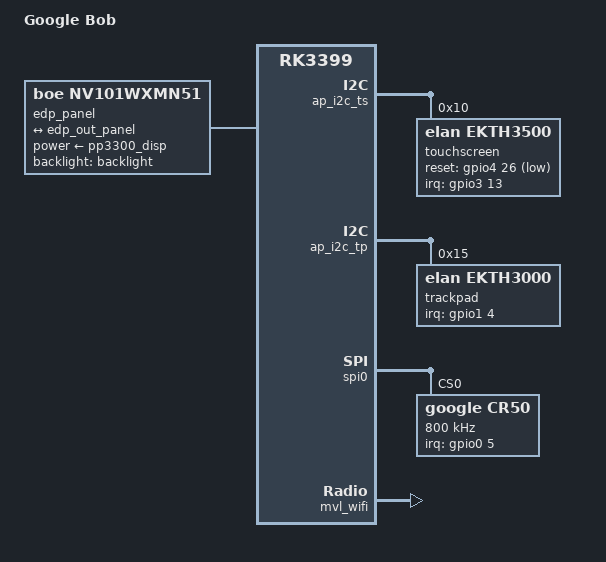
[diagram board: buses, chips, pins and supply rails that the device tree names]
// SPDX-License-Identifier: (GPL-2.0+ OR MIT)
/*
 * Google Gru-Bob Rev 4+ board device tree source
 *
 * Copyright 2018 Google, Inc
 */

/dts-v1/;
#include "rk3399-gru-chromebook.dtsi"

/ {
	model = "Google Bob";
	compatible = "google,bob-rev13", "google,bob-rev12",
		     "google,bob-rev11", "google,bob-rev10",
		     "google,bob-rev9", "google,bob-rev8",
		     "google,bob-rev7", "google,bob-rev6",
		     "google,bob-rev5", "google,bob-rev4",
		     "google,bob", "google,gru", "rockchip,rk3399";

	edp_panel: edp-panel {
		compatible = "boe,nv101wxmn51";
		backlight = <&backlight>;
		power-supply = <&pp3300_disp>;

		port {
			panel_in_edp: endpoint {
				remote-endpoint = <&edp_out_panel>;
			};
		};
	};
};

&ap_i2c_ts {
	touchscreen: touchscreen@10 {
		compatible = "elan,ekth3500";
		reg = <0x10>;
		interrupt-parent = <&gpio3>;
		interrupts = <13 IRQ_TYPE_LEVEL_LOW>;
		pinctrl-names = "default";
		pinctrl-0 = <&touch_int_l &touch_reset_l>;
		reset-gpios = <&gpio4 26 GPIO_ACTIVE_LOW>;
	};
};

&ap_i2c_tp {
	trackpad: trackpad@15 {
		compatible = "elan,ekth3000";
		reg = <0x15>;
		interrupt-parent = <&gpio1>;
		interrupts = <4 IRQ_TYPE_LEVEL_LOW>;
		pinctrl-names = "default";
		pinctrl-0 = <&trackpad_int_l>;
		wakeup-source;
	};
};

&backlight {
	pwms = <&cros_ec_pwm 0>;
};

&cpu_alert0 {
	temperature = <65000>;
};

&cpu_alert1 {
	temperature = <70000>;
};

&spi0 {
	status = "okay";

	cr50@0 {
		compatible = "google,cr50";
		reg = <0>;
		interrupt-parent = <&gpio0>;
		interrupts = <5 IRQ_TYPE_EDGE_RISING>;
		pinctrl-names = "default";
		pinctrl-0 = <&h1_int_od_l>;
		spi-max-frequency = <800000>;
	};
};

&mvl_wifi {
	marvell,caldata_00_txpwrlimit_2g_cfg_set = /bits/ 8 <
0x01 0x00 0x06 0x00 0x30 0x02 0x89 0x01 0x24 0x00 0x67 0x09 0x14 0x01 0x00 0x0d
0x01 0x0d 0x02 0x0d 0x03 0x0d 0x04 0x0d 0x05 0x0d 0x06 0x0d 0x07 0x0d 0x08 0x0d
0x09 0x0d 0x0a 0x0d 0x0b 0x0d 0x0c 0x0d 0x0d 0x0d 0x0e 0x0d 0x0f 0x0d 0x89 0x01
0x24 0x00 0x67 0x09 0x14 0x02 0x00 0x0d 0x01 0x0d 0x02 0x0d 0x03 0x0d 0x04 0x0d
0x05 0x0d 0x06 0x0d 0x07 0x0d 0x08 0x0d 0x09 0x0d 0x0a 0x0d 0x0b 0x0d 0x0c 0x0d
0x0d 0x0d 0x0e 0x0d 0x0f 0x0d 0x89 0x01 0x24 0x00 0x67 0x09 0x14 0x03 0x00 0x0d
0x01 0x0d 0x02 0x0d 0x03 0x0d 0x04 0x0d 0x05 0x0d 0x06 0x0d 0x07 0x0d 0x08 0x0d
0x09 0x0d 0x0a 0x0d 0x0b 0x0d 0x0c 0x0d 0x0d 0x0d 0x0e 0x0d 0x0f 0x0d 0x89 0x01
0x24 0x00 0x67 0x09 0x14 0x04 0x00 0x0d 0x01 0x0d 0x02 0x0d 0x03 0x0d 0x04 0x0d
0x05 0x0d 0x06 0x0d 0x07 0x0d 0x08 0x0d 0x09 0x0d 0x0a 0x0d 0x0b 0x0d 0x0c 0x0d
0x0d 0x0d 0x0e 0x0d 0x0f 0x0d 0x89 0x01 0x24 0x00 0x67 0x09 0x14 0x05 0x00 0x0d
0x01 0x0d 0x02 0x0d 0x03 0x0d 0x04 0x0d 0x05 0x0d 0x06 0x0d 0x07 0x0d 0x08 0x0d
0x09 0x0d 0x0a 0x0d 0x0b 0x0d 0x0c 0x0d 0x0d 0x0d 0x0e 0x0d 0x0f 0x0d 0x89 0x01
0x24 0x00 0x67 0x09 0x14 0x06 0x00 0x0d 0x01 0x0d 0x02 0x0d 0x03 0x0d 0x04 0x0d
0x05 0x0d 0x06 0x0d 0x07 0x0d 0x08 0x0d 0x09 0x0d 0x0a 0x0d 0x0b 0x0d 0x0c 0x0d
0x0d 0x0d 0x0e 0x0d 0x0f 0x0d 0x89 0x01 0x24 0x00 0x67 0x09 0x14 0x07 0x00 0x0d
0x01 0x0d 0x02 0x0d 0x03 0x0d 0x04 0x0d 0x05 0x0d 0x06 0x0d 0x07 0x0d 0x08 0x0d
0x09 0x0d 0x0a 0x0d 0x0b 0x0d 0x0c 0x0d 0x0d 0x0d 0x0e 0x0d 0x0f 0x0d 0x89 0x01
0x24 0x00 0x67 0x09 0x14 0x08 0x00 0x0d 0x01 0x0d 0x02 0x0d 0x03 0x0d 0x04 0x0d
0x05 0x0d 0x06 0x0d 0x07 0x0d 0x08 0x0d 0x09 0x0d 0x0a 0x0d 0x0b 0x0d 0x0c 0x0d
0x0d 0x0d 0x0e 0x0d 0x0f 0x0d 0x89 0x01 0x24 0x00 0x67 0x09 0x14 0x09 0x00 0x0d
0x01 0x0d 0x02 0x0d 0x03 0x0d 0x04 0x0d 0x05 0x0d 0x06 0x0d 0x07 0x0d 0x08 0x0d
0x09 0x0d 0x0a 0x0d 0x0b 0x0d 0x0c 0x0d 0x0d 0x0d 0x0e 0x0d 0x0f 0x0d 0x89 0x01
0x24 0x00 0x67 0x09 0x14 0x0a 0x00 0x0d 0x01 0x0d 0x02 0x0d 0x03 0x0d 0x04 0x0d
0x05 0x0d 0x06 0x0d 0x07 0x0d 0x08 0x0d 0x09 0x0d 0x0a 0x0d 0x0b 0x0d 0x0c 0x0d
0x0d 0x0d 0x0e 0x0d 0x0f 0x0d 0x89 0x01 0x24 0x00 0x67 0x09 0x14 0x0b 0x00 0x0d
0x01 0x0d 0x02 0x0d 0x03 0x0d 0x04 0x0d 0x05 0x0d 0x06 0x0d 0x07 0x0d 0x08 0x0d
0x09 0x0d 0x0a 0x0d 0x0b 0x0d 0x0c 0x0d 0x0d 0x0d 0x0e 0x0d 0x0f 0x0d 0x89 0x01
0x24 0x00 0x67 0x09 0x14 0x0c 0x00 0x0d 0x01 0x0d 0x02 0x0d 0x03 0x0d 0x04 0x0d
0x05 0x0d 0x06 0x0d 0x07 0x0d 0x08 0x0d 0x09 0x0d 0x0a 0x0d 0x0b 0x0d 0x0c 0x0d
0x0d 0x0d 0x0e 0x0d 0x0f 0x0d 0x89 0x01 0x24 0x00 0x67 0x09 0x14 0x0d 0x00 0x0d
0x01 0x0d 0x02 0x0d 0x03 0x0d 0x04 0x0d 0x05 0x0d 0x06 0x0d 0x07 0x0d 0x08 0x0d
0x09 0x0d 0x0a 0x0d 0x0b 0x0d 0x0c 0x0d 0x0d 0x0d 0x0e 0x0d 0x0f 0x0d 0x89 0x01
0x24 0x00 0x67 0x09 0x14 0x0e 0x00 0x0d 0x01 0x0d 0x02 0x0d 0x03 0x0d 0x04 0x0d
0x05 0x0d 0x06 0x0d 0x07 0x0d 0x08 0x0d 0x09 0x0d 0x0a 0x0d 0x0b 0x0d 0x0c 0x0d
0x0d 0x0d 0x0e 0x0d 0x0f 0x0d
	>;

	marvell,caldata_00_txpwrlimit_5g_cfg_set_sub0 = /bits/ 8 <
0x01 0x00 0x06 0x00 0x04 0x02 0x89 0x01 0x3c 0x00 0x88 0x13 0x14 0x24 0x00 0x0a
0x01 0x0a 0x02 0x0a 0x03 0x0a 0x04 0x0a 0x05 0x0a 0x06 0x0a 0x07 0x0a 0x08 0x0a
0x09 0x0a 0x0a 0x0a 0x0b 0x0a 0x0c 0x0a 0x0d 0x0a 0x0e 0x0a 0x0f 0x0a 0x10 0x0a
0x11 0x0a 0x12 0x0a 0x13 0x0a 0x14 0x0a 0x15 0x0a 0x16 0x0a 0x17 0x0a 0x18 0x0a
0x19 0x0a 0x1a 0x0a 0x1b 0x0a 0x89 0x01 0x3c 0x00 0x88 0x13 0x14 0x28 0x00 0x0a
0x01 0x0a 0x02 0x0a 0x03 0x0a 0x04 0x0a 0x05 0x0a 0x06 0x0a 0x07 0x0a 0x08 0x0a
0x09 0x0a 0x0a 0x0a 0x0b 0x0a 0x0c 0x0a 0x0d 0x0a 0x0e 0x0a 0x0f 0x0a 0x10 0x0a
0x11 0x0a 0x12 0x0a 0x13 0x0a 0x14 0x0a 0x15 0x0a 0x16 0x0a 0x17 0x0a 0x18 0x0a
0x19 0x0a 0x1a 0x0a 0x1b 0x0a 0x89 0x01 0x3c 0x00 0x88 0x13 0x14 0x2c 0x00 0x0a
0x01 0x0a 0x02 0x0a 0x03 0x0a 0x04 0x0a 0x05 0x0a 0x06 0x0a 0x07 0x0a 0x08 0x0a
0x09 0x0a 0x0a 0x0a 0x0b 0x0a 0x0c 0x0a 0x0d 0x0a 0x0e 0x0a 0x0f 0x0a 0x10 0x0a
0x11 0x0a 0x12 0x0a 0x13 0x0a 0x14 0x0a 0x15 0x0a 0x16 0x0a 0x17 0x0a 0x18 0x0a
0x19 0x0a 0x1a 0x0a 0x1b 0x0a 0x89 0x01 0x3c 0x00 0x88 0x13 0x14 0x30 0x00 0x0a
0x01 0x0a 0x02 0x0a 0x03 0x0a 0x04 0x0a 0x05 0x0a 0x06 0x0a 0x07 0x0a 0x08 0x0a
0x09 0x0a 0x0a 0x0a 0x0b 0x0a 0x0c 0x0a 0x0d 0x0a 0x0e 0x0a 0x0f 0x0a 0x10 0x0a
0x11 0x0a 0x12 0x0a 0x13 0x0a 0x14 0x0a 0x15 0x0a 0x16 0x0a 0x17 0x0a 0x18 0x0a
0x19 0x0a 0x1a 0x0a 0x1b 0x0a 0x89 0x01 0x3c 0x00 0x88 0x13 0x14 0x34 0x00 0x0a
0x01 0x0a 0x02 0x0a 0x03 0x0a 0x04 0x0a 0x05 0x0a 0x06 0x0a 0x07 0x0a 0x08 0x0a
0x09 0x0a 0x0a 0x0a 0x0b 0x0a 0x0c 0x0a 0x0d 0x0a 0x0e 0x0a 0x0f 0x0a 0x10 0x0a
0x11 0x0a 0x12 0x0a 0x13 0x0a 0x14 0x0a 0x15 0x0a 0x16 0x0a 0x17 0x0a 0x18 0x0a
0x19 0x0a 0x1a 0x0a 0x1b 0x0a 0x89 0x01 0x3c 0x00 0x88 0x13 0x14 0x38 0x00 0x0a
0x01 0x0a 0x02 0x0a 0x03 0x0a 0x04 0x0a 0x05 0x0a 0x06 0x0a 0x07 0x0a 0x08 0x0a
0x09 0x0a 0x0a 0x0a 0x0b 0x0a 0x0c 0x0a 0x0d 0x0a 0x0e 0x0a 0x0f 0x0a 0x10 0x0a
0x11 0x0a 0x12 0x0a 0x13 0x0a 0x14 0x0a 0x15 0x0a 0x16 0x0a 0x17 0x0a 0x18 0x0a
0x19 0x0a 0x1a 0x0a 0x1b 0x0a 0x89 0x01 0x3c 0x00 0x88 0x13 0x14 0x3c 0x00 0x0a
0x01 0x0a 0x02 0x0a 0x03 0x0a 0x04 0x0a 0x05 0x0a 0x06 0x0a 0x07 0x0a 0x08 0x0a
0x09 0x0a 0x0a 0x0a 0x0b 0x0a 0x0c 0x0a 0x0d 0x0a 0x0e 0x0a 0x0f 0x0a 0x10 0x0a
0x11 0x0a 0x12 0x0a 0x13 0x0a 0x14 0x0a 0x15 0x0a 0x16 0x0a 0x17 0x0a 0x18 0x0a
0x19 0x0a 0x1a 0x0a 0x1b 0x0a 0x89 0x01 0x3c 0x00 0x88 0x13 0x14 0x40 0x00 0x0a
0x01 0x0a 0x02 0x0a 0x03 0x0a 0x04 0x0a 0x05 0x0a 0x06 0x0a 0x07 0x0a 0x08 0x0a
0x09 0x0a 0x0a 0x0a 0x0b 0x0a 0x0c 0x0a 0x0d 0x0a 0x0e 0x0a 0x0f 0x0a 0x10 0x0a
0x11 0x0a 0x12 0x0a 0x13 0x0a 0x14 0x0a 0x15 0x0a 0x16 0x0a 0x17 0x0a 0x18 0x0a
0x19 0x0a 0x1a 0x0a 0x1b 0x0a
	>;

	marvell,caldata_00_txpwrlimit_5g_cfg_set_sub1 = /bits/ 8 <
0x01 0x00 0x06 0x00 0x04 0x03 0x89 0x01 0x3c 0x00 0x88 0x13 0x14 0x64 0x00 0x0a
0x01 0x0a 0x02 0x0a 0x03 0x0a 0x04 0x0a 0x05 0x0a 0x06 0x0a 0x07 0x0a 0x08 0x0a
0x09 0x0a 0x0a 0x0a 0x0b 0x0a 0x0c 0x0a 0x0d 0x0a 0x0e 0x0a 0x0f 0x0a 0x10 0x0a
0x11 0x0a 0x12 0x0a 0x13 0x0a 0x14 0x0a 0x15 0x0a 0x16 0x0a 0x17 0x0a 0x18 0x0a
0x19 0x0a 0x1a 0x0a 0x1b 0x0a 0x89 0x01 0x3c 0x00 0x88 0x13 0x14 0x68 0x00 0x0a
0x01 0x0a 0x02 0x0a 0x03 0x0a 0x04 0x0a 0x05 0x0a 0x06 0x0a 0x07 0x0a 0x08 0x0a
0x09 0x0a 0x0a 0x0a 0x0b 0x0a 0x0c 0x0a 0x0d 0x0a 0x0e 0x0a 0x0f 0x0a 0x10 0x0a
0x11 0x0a 0x12 0x0a 0x13 0x0a 0x14 0x0a 0x15 0x0a 0x16 0x0a 0x17 0x0a 0x18 0x0a
0x19 0x0a 0x1a 0x0a 0x1b 0x0a 0x89 0x01 0x3c 0x00 0x88 0x13 0x14 0x6c 0x00 0x0a
0x01 0x0a 0x02 0x0a 0x03 0x0a 0x04 0x0a 0x05 0x0a 0x06 0x0a 0x07 0x0a 0x08 0x0a
0x09 0x0a 0x0a 0x0a 0x0b 0x0a 0x0c 0x0a 0x0d 0x0a 0x0e 0x0a 0x0f 0x0a 0x10 0x0a
0x11 0x0a 0x12 0x0a 0x13 0x0a 0x14 0x0a 0x15 0x0a 0x16 0x0a 0x17 0x0a 0x18 0x0a
0x19 0x0a 0x1a 0x0a 0x1b 0x0a 0x89 0x01 0x3c 0x00 0x88 0x13 0x14 0x70 0x00 0x0a
0x01 0x0a 0x02 0x0a 0x03 0x0a 0x04 0x0a 0x05 0x0a 0x06 0x0a 0x07 0x0a 0x08 0x0a
0x09 0x0a 0x0a 0x0a 0x0b 0x0a 0x0c 0x0a 0x0d 0x0a 0x0e 0x0a 0x0f 0x0a 0x10 0x0a
0x11 0x0a 0x12 0x0a 0x13 0x0a 0x14 0x0a 0x15 0x0a 0x16 0x0a 0x17 0x0a 0x18 0x0a
0x19 0x0a 0x1a 0x0a 0x1b 0x0a 0x89 0x01 0x3c 0x00 0x88 0x13 0x14 0x74 0x00 0x0a
0x01 0x0a 0x02 0x0a 0x03 0x0a 0x04 0x0a 0x05 0x0a 0x06 0x0a 0x07 0x0a 0x08 0x0a
0x09 0x0a 0x0a 0x0a 0x0b 0x0a 0x0c 0x0a 0x0d 0x0a 0x0e 0x0a 0x0f 0x0a 0x10 0x0a
0x11 0x0a 0x12 0x0a 0x13 0x0a 0x14 0x0a 0x15 0x0a 0x16 0x0a 0x17 0x0a 0x18 0x0a
0x19 0x0a 0x1a 0x0a 0x1b 0x0a 0x89 0x01 0x3c 0x00 0x88 0x13 0x14 0x78 0x00 0x0a
0x01 0x0a 0x02 0x0a 0x03 0x0a 0x04 0x0a 0x05 0x0a 0x06 0x0a 0x07 0x0a 0x08 0x0a
0x09 0x0a 0x0a 0x0a 0x0b 0x0a 0x0c 0x0a 0x0d 0x0a 0x0e 0x0a 0x0f 0x0a 0x10 0x0a
0x11 0x0a 0x12 0x0a 0x13 0x0a 0x14 0x0a 0x15 0x0a 0x16 0x0a 0x17 0x0a 0x18 0x0a
0x19 0x0a 0x1a 0x0a 0x1b 0x0a 0x89 0x01 0x3c 0x00 0x88 0x13 0x14 0x7c 0x00 0x0a
0x01 0x0a 0x02 0x0a 0x03 0x0a 0x04 0x0a 0x05 0x0a 0x06 0x0a 0x07 0x0a 0x08 0x0a
0x09 0x0a 0x0a 0x0a 0x0b 0x0a 0x0c 0x0a 0x0d 0x0a 0x0e 0x0a 0x0f 0x0a 0x10 0x0a
0x11 0x0a 0x12 0x0a 0x13 0x0a 0x14 0x0a 0x15 0x0a 0x16 0x0a 0x17 0x0a 0x18 0x0a
0x19 0x0a 0x1a 0x0a 0x1b 0x0a 0x89 0x01 0x3c 0x00 0x88 0x13 0x14 0x80 0x00 0x0a
0x01 0x0a 0x02 0x0a 0x03 0x0a 0x04 0x0a 0x05 0x0a 0x06 0x0a 0x07 0x0a 0x08 0x0a
0x09 0x0a 0x0a 0x0a 0x0b 0x0a 0x0c 0x0a 0x0d 0x0a 0x0e 0x0a 0x0f 0x0a 0x10 0x0a
0x11 0x0a 0x12 0x0a 0x13 0x0a 0x14 0x0a 0x15 0x0a 0x16 0x0a 0x17 0x0a 0x18 0x0a
0x19 0x0a 0x1a 0x0a 0x1b 0x0a 0x89 0x01 0x3c 0x00 0x88 0x13 0x14 0x84 0x00 0x0a
0x01 0x0a 0x02 0x0a 0x03 0x0a 0x04 0x0a 0x05 0x0a 0x06 0x0a 0x07 0x0a 0x08 0x0a
0x09 0x0a 0x0a 0x0a 0x0b 0x0a 0x0c 0x0a 0x0d 0x0a 0x0e 0x0a 0x0f 0x0a 0x10 0x0a
0x11 0x0a 0x12 0x0a 0x13 0x0a 0x14 0x0a 0x15 0x0a 0x16 0x0a 0x17 0x0a 0x18 0x0a
0x19 0x0a 0x1a 0x0a 0x1b 0x0a 0x89 0x01 0x3c 0x00 0x88 0x13 0x14 0x88 0x00 0x0a
0x01 0x0a 0x02 0x0a 0x03 0x0a 0x04 0x0a 0x05 0x0a 0x06 0x0a 0x07 0x0a 0x08 0x0a
0x09 0x0a 0x0a 0x0a 0x0b 0x0a 0x0c 0x0a 0x0d 0x0a 0x0e 0x0a 0x0f 0x0a 0x10 0x0a
0x11 0x0a 0x12 0x0a 0x13 0x0a 0x14 0x0a 0x15 0x0a 0x16 0x0a 0x17 0x0a 0x18 0x0a
0x19 0x0a 0x1a 0x0a 0x1b 0x0a 0x89 0x01 0x3c 0x00 0x88 0x13 0x14 0x8c 0x00 0x0a
0x01 0x0a 0x02 0x0a 0x03 0x0a 0x04 0x0a 0x05 0x0a 0x06 0x0a 0x07 0x0a 0x08 0x0a
0x09 0x0a 0x0a 0x0a 0x0b 0x0a 0x0c 0x0a 0x0d 0x0a 0x0e 0x0a 0x0f 0x0a 0x10 0x0a
0x11 0x0a 0x12 0x0a 0x13 0x0a 0x14 0x0a 0x15 0x0a 0x16 0x0a 0x17 0x0a 0x18 0x0a
0x19 0x0a 0x1a 0x0a 0x1b 0x0a 0x89 0x01 0x3c 0x00 0x88 0x13 0x14 0x90 0x00 0x0a
0x01 0x0a 0x02 0x0a 0x03 0x0a 0x04 0x0a 0x05 0x0a 0x06 0x0a 0x07 0x0a 0x08 0x0a
0x09 0x0a 0x0a 0x0a 0x0b 0x0a 0x0c 0x0a 0x0d 0x0a 0x0e 0x0a 0x0f 0x0a 0x10 0x0a
0x11 0x0a 0x12 0x0a 0x13 0x0a 0x14 0x0a 0x15 0x0a 0x16 0x0a 0x17 0x0a 0x18 0x0a
0x19 0x0a 0x1a 0x0a 0x1b 0x0a
	>;

	marvell,caldata_00_txpwrlimit_5g_cfg_set_sub2 = /bits/ 8 <
0x01 0x00 0x06 0x00 0x44 0x01 0x89 0x01 0x3c 0x00 0x88 0x13 0x14 0x95 0x00 0x0a
0x01 0x0a 0x02 0x0a 0x03 0x0a 0x04 0x0a 0x05 0x0a 0x06 0x0a 0x07 0x0a 0x08 0x0a
0x09 0x0a 0x0a 0x0a 0x0b 0x0a 0x0c 0x0a 0x0d 0x0a 0x0e 0x0a 0x0f 0x0a 0x10 0x0a
0x11 0x0a 0x12 0x0a 0x13 0x0a 0x14 0x0a 0x15 0x0a 0x16 0x0a 0x17 0x0a 0x18 0x0a
0x19 0x0a 0x1a 0x0a 0x1b 0x0a 0x89 0x01 0x3c 0x00 0x88 0x13 0x14 0x99 0x00 0x0a
0x01 0x0a 0x02 0x0a 0x03 0x0a 0x04 0x0a 0x05 0x0a 0x06 0x0a 0x07 0x0a 0x08 0x0a
0x09 0x0a 0x0a 0x0a 0x0b 0x0a 0x0c 0x0a 0x0d 0x0a 0x0e 0x0a 0x0f 0x0a 0x10 0x0a
0x11 0x0a 0x12 0x0a 0x13 0x0a 0x14 0x0a 0x15 0x0a 0x16 0x0a 0x17 0x0a 0x18 0x0a
0x19 0x0a 0x1a 0x0a 0x1b 0x0a 0x89 0x01 0x3c 0x00 0x88 0x13 0x14 0x9d 0x00 0x0a
0x01 0x0a 0x02 0x0a 0x03 0x0a 0x04 0x0a 0x05 0x0a 0x06 0x0a 0x07 0x0a 0x08 0x0a
0x09 0x0a 0x0a 0x0a 0x0b 0x0a 0x0c 0x0a 0x0d 0x0a 0x0e 0x0a 0x0f 0x0a 0x10 0x0a
0x11 0x0a 0x12 0x0a 0x13 0x0a 0x14 0x0a 0x15 0x0a 0x16 0x0a 0x17 0x0a 0x18 0x0a
0x19 0x0a 0x1a 0x0a 0x1b 0x0a 0x89 0x01 0x3c 0x00 0x88 0x13 0x14 0xa1 0x00 0x0a
0x01 0x0a 0x02 0x0a 0x03 0x0a 0x04 0x0a 0x05 0x0a 0x06 0x0a 0x07 0x0a 0x08 0x0a
0x09 0x0a 0x0a 0x0a 0x0b 0x0a 0x0c 0x0a 0x0d 0x0a 0x0e 0x0a 0x0f 0x0a 0x10 0x0a
0x11 0x0a 0x12 0x0a 0x13 0x0a 0x14 0x0a 0x15 0x0a 0x16 0x0a 0x17 0x0a 0x18 0x0a
0x19 0x0a 0x1a 0x0a 0x1b 0x0a 0x89 0x01 0x3c 0x00 0x88 0x13 0x14 0xa5 0x00 0x0a
0x01 0x0a 0x02 0x0a 0x03 0x0a 0x04 0x0a 0x05 0x0a 0x06 0x0a 0x07 0x0a 0x08 0x0a
0x09 0x0a 0x0a 0x0a 0x0b 0x0a 0x0c 0x0a 0x0d 0x0a 0x0e 0x0a 0x0f 0x0a 0x10 0x0a
0x11 0x0a 0x12 0x0a 0x13 0x0a 0x14 0x0a 0x15 0x0a 0x16 0x0a 0x17 0x0a 0x18 0x0a
0x19 0x0a 0x1a 0x0a 0x1b 0x0a
	>;

	marvell,caldata_00_txpwrlimit_5g_cfg_set_sub3 = /bits/ 8 <
0x01 0x00 0x06 0x00 0x84 0x03 0x89 0x01 0x3c 0x00 0xa0 0x0f 0x14 0xb7 0x00 0x0a
0x01 0x0a 0x02 0x0a 0x03 0x0a 0x04 0x0a 0x05 0x0a 0x06 0x0a 0x07 0x0a 0x08 0x0a
0x09 0x0a 0x0a 0x0a 0x0b 0x0a 0x0c 0x0a 0x0d 0x0a 0x0e 0x0a 0x0f 0x0a 0x10 0x0a
0x11 0x0a 0x12 0x0a 0x13 0x0a 0x14 0x0a 0x15 0x0a 0x16 0x0a 0x17 0x0a 0x18 0x0a
0x19 0x0a 0x1a 0x0a 0x1b 0x0a 0x89 0x01 0x3c 0x00 0xa0 0x0f 0x14 0xb8 0x00 0x0a
0x01 0x0a 0x02 0x0a 0x03 0x0a 0x04 0x0a 0x05 0x0a 0x06 0x0a 0x07 0x0a 0x08 0x0a
0x09 0x0a 0x0a 0x0a 0x0b 0x0a 0x0c 0x0a 0x0d 0x0a 0x0e 0x0a 0x0f 0x0a 0x10 0x0a
0x11 0x0a 0x12 0x0a 0x13 0x0a 0x14 0x0a 0x15 0x0a 0x16 0x0a 0x17 0x0a 0x18 0x0a
0x19 0x0a 0x1a 0x0a 0x1b 0x0a 0x89 0x01 0x3c 0x00 0xa0 0x0f 0x14 0xb9 0x00 0x0a
0x01 0x0a 0x02 0x0a 0x03 0x0a 0x04 0x0a 0x05 0x0a 0x06 0x0a 0x07 0x0a 0x08 0x0a
0x09 0x0a 0x0a 0x0a 0x0b 0x0a 0x0c 0x0a 0x0d 0x0a 0x0e 0x0a 0x0f 0x0a 0x10 0x0a
0x11 0x0a 0x12 0x0a 0x13 0x0a 0x14 0x0a 0x15 0x0a 0x16 0x0a 0x17 0x0a 0x18 0x0a
0x19 0x0a 0x1a 0x0a 0x1b 0x0a 0x89 0x01 0x3c 0x00 0xa0 0x0f 0x14 0xbb 0x00 0x0a
0x01 0x0a 0x02 0x0a 0x03 0x0a 0x04 0x0a 0x05 0x0a 0x06 0x0a 0x07 0x0a 0x08 0x0a
0x09 0x0a 0x0a 0x0a 0x0b 0x0a 0x0c 0x0a 0x0d 0x0a 0x0e 0x0a 0x0f 0x0a 0x10 0x0a
0x11 0x0a 0x12 0x0a 0x13 0x0a 0x14 0x0a 0x15 0x0a 0x16 0x0a 0x17 0x0a 0x18 0x0a
0x19 0x0a 0x1a 0x0a 0x1b 0x0a 0x89 0x01 0x3c 0x00 0xa0 0x0f 0x14 0xbc 0x00 0x0a
0x01 0x0a 0x02 0x0a 0x03 0x0a 0x04 0x0a 0x05 0x0a 0x06 0x0a 0x07 0x0a 0x08 0x0a
0x09 0x0a 0x0a 0x0a 0x0b 0x0a 0x0c 0x0a 0x0d 0x0a 0x0e 0x0a 0x0f 0x0a 0x10 0x0a
0x11 0x0a 0x12 0x0a 0x13 0x0a 0x14 0x0a 0x15 0x0a 0x16 0x0a 0x17 0x0a 0x18 0x0a
0x19 0x0a 0x1a 0x0a 0x1b 0x0a 0x89 0x01 0x3c 0x00 0xa0 0x0f 0x14 0xbd 0x00 0x0a
0x01 0x0a 0x02 0x0a 0x03 0x0a 0x04 0x0a 0x05 0x0a 0x06 0x0a 0x07 0x0a 0x08 0x0a
0x09 0x0a 0x0a 0x0a 0x0b 0x0a 0x0c 0x0a 0x0d 0x0a 0x0e 0x0a 0x0f 0x0a 0x10 0x0a
0x11 0x0a 0x12 0x0a 0x13 0x0a 0x14 0x0a 0x15 0x0a 0x16 0x0a 0x17 0x0a 0x18 0x0a
0x19 0x0a 0x1a 0x0a 0x1b 0x0a 0x89 0x01 0x3c 0x00 0xa0 0x0f 0x14 0xc0 0x00 0x0a
0x01 0x0a 0x02 0x0a 0x03 0x0a 0x04 0x0a 0x05 0x0a 0x06 0x0a 0x07 0x0a 0x08 0x0a
0x09 0x0a 0x0a 0x0a 0x0b 0x0a 0x0c 0x0a 0x0d 0x0a 0x0e 0x0a 0x0f 0x0a 0x10 0x0a
0x11 0x0a 0x12 0x0a 0x13 0x0a 0x14 0x0a 0x15 0x0a 0x16 0x0a 0x17 0x0a 0x18 0x0a
0x19 0x0a 0x1a 0x0a 0x1b 0x0a 0x89 0x01 0x3c 0x00 0xa0 0x0f 0x14 0xc4 0x00 0x0a
0x01 0x0a 0x02 0x0a 0x03 0x0a 0x04 0x0a 0x05 0x0a 0x06 0x0a 0x07 0x0a 0x08 0x0a
0x09 0x0a 0x0a 0x0a 0x0b 0x0a 0x0c 0x0a 0x0d 0x0a 0x0e 0x0a 0x0f 0x0a 0x10 0x0a
0x11 0x0a 0x12 0x0a 0x13 0x0a 0x14 0x0a 0x15 0x0a 0x16 0x0a 0x17 0x0a 0x18 0x0a
0x19 0x0a 0x1a 0x0a 0x1b 0x0a 0x89 0x01 0x3c 0x00 0x88 0x13 0x14 0x07 0x00 0x0a
0x01 0x0a 0x02 0x0a 0x03 0x0a 0x04 0x0a 0x05 0x0a 0x06 0x0a 0x07 0x0a 0x08 0x0a
0x09 0x0a 0x0a 0x0a 0x0b 0x0a 0x0c 0x0a 0x0d 0x0a 0x0e 0x0a 0x0f 0x0a 0x10 0x0a
0x11 0x0a 0x12 0x0a 0x13 0x0a 0x14 0x0a 0x15 0x0a 0x16 0x0a 0x17 0x0a 0x18 0x0a
0x19 0x0a 0x1a 0x0a 0x1b 0x0a 0x89 0x01 0x3c 0x00 0x88 0x13 0x14 0x08 0x00 0x0a
0x01 0x0a 0x02 0x0a 0x03 0x0a 0x04 0x0a 0x05 0x0a 0x06 0x0a 0x07 0x0a 0x08 0x0a
0x09 0x0a 0x0a 0x0a 0x0b 0x0a 0x0c 0x0a 0x0d 0x0a 0x0e 0x0a 0x0f 0x0a 0x10 0x0a
0x11 0x0a 0x12 0x0a 0x13 0x0a 0x14 0x0a 0x15 0x0a 0x16 0x0a 0x17 0x0a 0x18 0x0a
0x19 0x0a 0x1a 0x0a 0x1b 0x0a 0x89 0x01 0x3c 0x00 0x88 0x13 0x14 0x0b 0x00 0x0a
0x01 0x0a 0x02 0x0a 0x03 0x0a 0x04 0x0a 0x05 0x0a 0x06 0x0a 0x07 0x0a 0x08 0x0a
0x09 0x0a 0x0a 0x0a 0x0b 0x0a 0x0c 0x0a 0x0d 0x0a 0x0e 0x0a 0x0f 0x0a 0x10 0x0a
0x11 0x0a 0x12 0x0a 0x13 0x0a 0x14 0x0a 0x15 0x0a 0x16 0x0a 0x17 0x0a 0x18 0x0a
0x19 0x0a 0x1a 0x0a 0x1b 0x0a 0x89 0x01 0x3c 0x00 0x88 0x13 0x14 0x0c 0x00 0x0a
0x01 0x0a 0x02 0x0a 0x03 0x0a 0x04 0x0a 0x05 0x0a 0x06 0x0a 0x07 0x0a 0x08 0x0a
0x09 0x0a 0x0a 0x0a 0x0b 0x0a 0x0c 0x0a 0x0d 0x0a 0x0e 0x0a 0x0f 0x0a 0x10 0x0a
0x11 0x0a 0x12 0x0a 0x13 0x0a 0x14 0x0a 0x15 0x0a 0x16 0x0a 0x17 0x0a 0x18 0x0a
0x19 0x0a 0x1a 0x0a 0x1b 0x0a 0x89 0x01 0x3c 0x00 0x88 0x13 0x14 0x10 0x00 0x0a
0x01 0x0a 0x02 0x0a 0x03 0x0a 0x04 0x0a 0x05 0x0a 0x06 0x0a 0x07 0x0a 0x08 0x0a
0x09 0x0a 0x0a 0x0a 0x0b 0x0a 0x0c 0x0a 0x0d 0x0a 0x0e 0x0a 0x0f 0x0a 0x10 0x0a
0x11 0x0a 0x12 0x0a 0x13 0x0a 0x14 0x0a 0x15 0x0a 0x16 0x0a 0x17 0x0a 0x18 0x0a
0x19 0x0a 0x1a 0x0a 0x1b 0x0a 0x89 0x01 0x3c 0x00 0x88 0x13 0x14 0x22 0x00 0x0a
0x01 0x0a 0x02 0x0a 0x03 0x0a 0x04 0x0a 0x05 0x0a 0x06 0x0a 0x07 0x0a 0x08 0x0a
0x09 0x0a 0x0a 0x0a 0x0b 0x0a 0x0c 0x0a 0x0d 0x0a 0x0e 0x0a 0x0f 0x0a 0x10 0x0a
0x11 0x0a 0x12 0x0a 0x13 0x0a 0x14 0x0a 0x15 0x0a 0x16 0x0a 0x17 0x0a 0x18 0x0a
0x19 0x0a 0x1a 0x0a 0x1b 0x0a
	>;

	marvell,caldata_01_txpwrlimit_2g_cfg_set = /bits/ 8 <
0x01 0x00 0x06 0x00 0x30 0x02 0x89 0x01 0x24 0x00 0x67 0x09 0x14 0x01 0x00 0x0f
0x01 0x0f 0x02 0x0f 0x03 0x0f 0x04 0x0f 0x05 0x0f 0x06 0x0f 0x07 0x0f 0x08 0x0f
0x09 0x0f 0x0a 0x0f 0x0b 0x0f 0x0c 0x0f 0x0d 0x0f 0x0e 0x0f 0x0f 0x0f 0x89 0x01
0x24 0x00 0x67 0x09 0x14 0x02 0x00 0x0f 0x01 0x0f 0x02 0x0f 0x03 0x0f 0x04 0x0f
0x05 0x0f 0x06 0x0f 0x07 0x0f 0x08 0x0f 0x09 0x0f 0x0a 0x0f 0x0b 0x0f 0x0c 0x0f
0x0d 0x0f 0x0e 0x0f 0x0f 0x0f 0x89 0x01 0x24 0x00 0x67 0x09 0x14 0x03 0x00 0x0f
0x01 0x0f 0x02 0x0f 0x03 0x0f 0x04 0x0f 0x05 0x0f 0x06 0x0f 0x07 0x0f 0x08 0x0f
0x09 0x0f 0x0a 0x0f 0x0b 0x0f 0x0c 0x0f 0x0d 0x0f 0x0e 0x0f 0x0f 0x0f 0x89 0x01
0x24 0x00 0x67 0x09 0x14 0x04 0x00 0x0f 0x01 0x0f 0x02 0x0f 0x03 0x0f 0x04 0x0f
0x05 0x0f 0x06 0x0f 0x07 0x0f 0x08 0x0f 0x09 0x0f 0x0a 0x0f 0x0b 0x0f 0x0c 0x0f
0x0d 0x0f 0x0e 0x0f 0x0f 0x0f 0x89 0x01 0x24 0x00 0x67 0x09 0x14 0x05 0x00 0x0f
0x01 0x0f 0x02 0x0f 0x03 0x0f 0x04 0x0f 0x05 0x0f 0x06 0x0f 0x07 0x0f 0x08 0x0f
0x09 0x0f 0x0a 0x0f 0x0b 0x0f 0x0c 0x0f 0x0d 0x0f 0x0e 0x0f 0x0f 0x0f 0x89 0x01
0x24 0x00 0x67 0x09 0x14 0x06 0x00 0x0f 0x01 0x0f 0x02 0x0f 0x03 0x0f 0x04 0x0f
0x05 0x0f 0x06 0x0f 0x07 0x0f 0x08 0x0f 0x09 0x0f 0x0a 0x0f 0x0b 0x0f 0x0c 0x0f
0x0d 0x0f 0x0e 0x0f 0x0f 0x0f 0x89 0x01 0x24 0x00 0x67 0x09 0x14 0x07 0x00 0x0f
0x01 0x0f 0x02 0x0f 0x03 0x0f 0x04 0x0f 0x05 0x0f 0x06 0x0f 0x07 0x0f 0x08 0x0f
0x09 0x0f 0x0a 0x0f 0x0b 0x0f 0x0c 0x0f 0x0d 0x0f 0x0e 0x0f 0x0f 0x0f 0x89 0x01
0x24 0x00 0x67 0x09 0x14 0x08 0x00 0x0f 0x01 0x0f 0x02 0x0f 0x03 0x0f 0x04 0x0f
0x05 0x0f 0x06 0x0f 0x07 0x0f 0x08 0x0f 0x09 0x0f 0x0a 0x0f 0x0b 0x0f 0x0c 0x0f
0x0d 0x0f 0x0e 0x0f 0x0f 0x0f 0x89 0x01 0x24 0x00 0x67 0x09 0x14 0x09 0x00 0x0f
0x01 0x0f 0x02 0x0f 0x03 0x0f 0x04 0x0f 0x05 0x0f 0x06 0x0f 0x07 0x0f 0x08 0x0f
0x09 0x0f 0x0a 0x0f 0x0b 0x0f 0x0c 0x0f 0x0d 0x0f 0x0e 0x0f 0x0f 0x0f 0x89 0x01
0x24 0x00 0x67 0x09 0x14 0x0a 0x00 0x0f 0x01 0x0f 0x02 0x0f 0x03 0x0f 0x04 0x0f
0x05 0x0f 0x06 0x0f 0x07 0x0f 0x08 0x0f 0x09 0x0f 0x0a 0x0f 0x0b 0x0f 0x0c 0x0f
0x0d 0x0f 0x0e 0x0f 0x0f 0x0f 0x89 0x01 0x24 0x00 0x67 0x09 0x14 0x0b 0x00 0x0f
0x01 0x0f 0x02 0x0f 0x03 0x0f 0x04 0x0f 0x05 0x0f 0x06 0x0f 0x07 0x0f 0x08 0x0f
0x09 0x0f 0x0a 0x0f 0x0b 0x0f 0x0c 0x0f 0x0d 0x0f 0x0e 0x0f 0x0f 0x0f 0x89 0x01
0x24 0x00 0x67 0x09 0x14 0x0c 0x00 0x0f 0x01 0x0f 0x02 0x0f 0x03 0x0f 0x04 0x0f
0x05 0x0f 0x06 0x0f 0x07 0x0f 0x08 0x0f 0x09 0x0f 0x0a 0x0f 0x0b 0x0f 0x0c 0x0f
0x0d 0x0f 0x0e 0x0f 0x0f 0x0f 0x89 0x01 0x24 0x00 0x67 0x09 0x14 0x0d 0x00 0x0f
0x01 0x0f 0x02 0x0f 0x03 0x0f 0x04 0x0f 0x05 0x0f 0x06 0x0f 0x07 0x0f 0x08 0x0f
0x09 0x0f 0x0a 0x0f 0x0b 0x0f 0x0c 0x0f 0x0d 0x0f 0x0e 0x0f 0x0f 0x0f 0x89 0x01
0x24 0x00 0x67 0x09 0x14 0x0e 0x00 0x0f 0x01 0x0f 0x02 0x0f 0x03 0x0f 0x04 0x0f
0x05 0x0f 0x06 0x0f 0x07 0x0f 0x08 0x0f 0x09 0x0f 0x0a 0x0f 0x0b 0x0f 0x0c 0x0f
0x0d 0x0f 0x0e 0x0f 0x0f 0x0f
	>;

	marvell,caldata_01_txpwrlimit_5g_cfg_set_sub0 = /bits/ 8 <
0x01 0x00 0x06 0x00 0x04 0x02 0x89 0x01 0x3c 0x00 0x88 0x13 0x14 0x24 0x00 0x0a
0x01 0x0a 0x02 0x0a 0x03 0x0a 0x04 0x0a 0x05 0x0a 0x06 0x0a 0x07 0x0a 0x08 0x0a
0x09 0x0a 0x0a 0x0a 0x0b 0x0a 0x0c 0x0a 0x0d 0x0a 0x0e 0x0a 0x0f 0x0a 0x10 0x0a
0x11 0x0a 0x12 0x0a 0x13 0x0a 0x14 0x0a 0x15 0x0a 0x16 0x0a 0x17 0x0a 0x18 0x0a
0x19 0x0a 0x1a 0x0a 0x1b 0x0a 0x89 0x01 0x3c 0x00 0x88 0x13 0x14 0x28 0x00 0x0a
0x01 0x0a 0x02 0x0a 0x03 0x0a 0x04 0x0a 0x05 0x0a 0x06 0x0a 0x07 0x0a 0x08 0x0a
0x09 0x0a 0x0a 0x0a 0x0b 0x0a 0x0c 0x0a 0x0d 0x0a 0x0e 0x0a 0x0f 0x0a 0x10 0x0a
0x11 0x0a 0x12 0x0a 0x13 0x0a 0x14 0x0a 0x15 0x0a 0x16 0x0a 0x17 0x0a 0x18 0x0a
0x19 0x0a 0x1a 0x0a 0x1b 0x0a 0x89 0x01 0x3c 0x00 0x88 0x13 0x14 0x2c 0x00 0x0a
0x01 0x0a 0x02 0x0a 0x03 0x0a 0x04 0x0a 0x05 0x0a 0x06 0x0a 0x07 0x0a 0x08 0x0a
0x09 0x0a 0x0a 0x0a 0x0b 0x0a 0x0c 0x0a 0x0d 0x0a 0x0e 0x0a 0x0f 0x0a 0x10 0x0a
0x11 0x0a 0x12 0x0a 0x13 0x0a 0x14 0x0a 0x15 0x0a 0x16 0x0a 0x17 0x0a 0x18 0x0a
0x19 0x0a 0x1a 0x0a 0x1b 0x0a 0x89 0x01 0x3c 0x00 0x88 0x13 0x14 0x30 0x00 0x0a
0x01 0x0a 0x02 0x0a 0x03 0x0a 0x04 0x0a 0x05 0x0a 0x06 0x0a 0x07 0x0a 0x08 0x0a
0x09 0x0a 0x0a 0x0a 0x0b 0x0a 0x0c 0x0a 0x0d 0x0a 0x0e 0x0a 0x0f 0x0a 0x10 0x0a
0x11 0x0a 0x12 0x0a 0x13 0x0a 0x14 0x0a 0x15 0x0a 0x16 0x0a 0x17 0x0a 0x18 0x0a
0x19 0x0a 0x1a 0x0a 0x1b 0x0a 0x89 0x01 0x3c 0x00 0x88 0x13 0x14 0x34 0x00 0x0a
0x01 0x0a 0x02 0x0a 0x03 0x0a 0x04 0x0a 0x05 0x0a 0x06 0x0a 0x07 0x0a 0x08 0x0a
0x09 0x0a 0x0a 0x0a 0x0b 0x0a 0x0c 0x0a 0x0d 0x0a 0x0e 0x0a 0x0f 0x0a 0x10 0x0a
0x11 0x0a 0x12 0x0a 0x13 0x0a 0x14 0x0a 0x15 0x0a 0x16 0x0a 0x17 0x0a 0x18 0x0a
0x19 0x0a 0x1a 0x0a 0x1b 0x0a 0x89 0x01 0x3c 0x00 0x88 0x13 0x14 0x38 0x00 0x0a
0x01 0x0a 0x02 0x0a 0x03 0x0a 0x04 0x0a 0x05 0x0a 0x06 0x0a 0x07 0x0a 0x08 0x0a
0x09 0x0a 0x0a 0x0a 0x0b 0x0a 0x0c 0x0a 0x0d 0x0a 0x0e 0x0a 0x0f 0x0a 0x10 0x0a
0x11 0x0a 0x12 0x0a 0x13 0x0a 0x14 0x0a 0x15 0x0a 0x16 0x0a 0x17 0x0a 0x18 0x0a
0x19 0x0a 0x1a 0x0a 0x1b 0x0a 0x89 0x01 0x3c 0x00 0x88 0x13 0x14 0x3c 0x00 0x0a
0x01 0x0a 0x02 0x0a 0x03 0x0a 0x04 0x0a 0x05 0x0a 0x06 0x0a 0x07 0x0a 0x08 0x0a
0x09 0x0a 0x0a 0x0a 0x0b 0x0a 0x0c 0x0a 0x0d 0x0a 0x0e 0x0a 0x0f 0x0a 0x10 0x0a
0x11 0x0a 0x12 0x0a 0x13 0x0a 0x14 0x0a 0x15 0x0a 0x16 0x0a 0x17 0x0a 0x18 0x0a
0x19 0x0a 0x1a 0x0a 0x1b 0x0a 0x89 0x01 0x3c 0x00 0x88 0x13 0x14 0x40 0x00 0x0a
0x01 0x0a 0x02 0x0a 0x03 0x0a 0x04 0x0a 0x05 0x0a 0x06 0x0a 0x07 0x0a 0x08 0x0a
0x09 0x0a 0x0a 0x0a 0x0b 0x0a 0x0c 0x0a 0x0d 0x0a 0x0e 0x0a 0x0f 0x0a 0x10 0x0a
0x11 0x0a 0x12 0x0a 0x13 0x0a 0x14 0x0a 0x15 0x0a 0x16 0x0a 0x17 0x0a 0x18 0x0a
0x19 0x0a 0x1a 0x0a 0x1b 0x0a
	>;

	marvell,caldata_01_txpwrlimit_5g_cfg_set_sub1 = /bits/ 8 <
0x01 0x00 0x06 0x00 0x04 0x03 0x89 0x01 0x3c 0x00 0x88 0x13 0x14 0x64 0x00 0x0a
0x01 0x0a 0x02 0x0a 0x03 0x0a 0x04 0x0a 0x05 0x0a 0x06 0x0a 0x07 0x0a 0x08 0x0a
0x09 0x0a 0x0a 0x0a 0x0b 0x0a 0x0c 0x0a 0x0d 0x0a 0x0e 0x0a 0x0f 0x0a 0x10 0x0a
0x11 0x0a 0x12 0x0a 0x13 0x0a 0x14 0x0a 0x15 0x0a 0x16 0x0a 0x17 0x0a 0x18 0x0a
0x19 0x0a 0x1a 0x0a 0x1b 0x0a 0x89 0x01 0x3c 0x00 0x88 0x13 0x14 0x68 0x00 0x0a
0x01 0x0a 0x02 0x0a 0x03 0x0a 0x04 0x0a 0x05 0x0a 0x06 0x0a 0x07 0x0a 0x08 0x0a
0x09 0x0a 0x0a 0x0a 0x0b 0x0a 0x0c 0x0a 0x0d 0x0a 0x0e 0x0a 0x0f 0x0a 0x10 0x0a
0x11 0x0a 0x12 0x0a 0x13 0x0a 0x14 0x0a 0x15 0x0a 0x16 0x0a 0x17 0x0a 0x18 0x0a
0x19 0x0a 0x1a 0x0a 0x1b 0x0a 0x89 0x01 0x3c 0x00 0x88 0x13 0x14 0x6c 0x00 0x0a
0x01 0x0a 0x02 0x0a 0x03 0x0a 0x04 0x0a 0x05 0x0a 0x06 0x0a 0x07 0x0a 0x08 0x0a
0x09 0x0a 0x0a 0x0a 0x0b 0x0a 0x0c 0x0a 0x0d 0x0a 0x0e 0x0a 0x0f 0x0a 0x10 0x0a
0x11 0x0a 0x12 0x0a 0x13 0x0a 0x14 0x0a 0x15 0x0a 0x16 0x0a 0x17 0x0a 0x18 0x0a
0x19 0x0a 0x1a 0x0a 0x1b 0x0a 0x89 0x01 0x3c 0x00 0x88 0x13 0x14 0x70 0x00 0x0a
0x01 0x0a 0x02 0x0a 0x03 0x0a 0x04 0x0a 0x05 0x0a 0x06 0x0a 0x07 0x0a 0x08 0x0a
0x09 0x0a 0x0a 0x0a 0x0b 0x0a 0x0c 0x0a 0x0d 0x0a 0x0e 0x0a 0x0f 0x0a 0x10 0x0a
0x11 0x0a 0x12 0x0a 0x13 0x0a 0x14 0x0a 0x15 0x0a 0x16 0x0a 0x17 0x0a 0x18 0x0a
0x19 0x0a 0x1a 0x0a 0x1b 0x0a 0x89 0x01 0x3c 0x00 0x88 0x13 0x14 0x74 0x00 0x0a
0x01 0x0a 0x02 0x0a 0x03 0x0a 0x04 0x0a 0x05 0x0a 0x06 0x0a 0x07 0x0a 0x08 0x0a
0x09 0x0a 0x0a 0x0a 0x0b 0x0a 0x0c 0x0a 0x0d 0x0a 0x0e 0x0a 0x0f 0x0a 0x10 0x0a
0x11 0x0a 0x12 0x0a 0x13 0x0a 0x14 0x0a 0x15 0x0a 0x16 0x0a 0x17 0x0a 0x18 0x0a
0x19 0x0a 0x1a 0x0a 0x1b 0x0a 0x89 0x01 0x3c 0x00 0x88 0x13 0x14 0x78 0x00 0x0a
0x01 0x0a 0x02 0x0a 0x03 0x0a 0x04 0x0a 0x05 0x0a 0x06 0x0a 0x07 0x0a 0x08 0x0a
0x09 0x0a 0x0a 0x0a 0x0b 0x0a 0x0c 0x0a 0x0d 0x0a 0x0e 0x0a 0x0f 0x0a 0x10 0x0a
0x11 0x0a 0x12 0x0a 0x13 0x0a 0x14 0x0a 0x15 0x0a 0x16 0x0a 0x17 0x0a 0x18 0x0a
0x19 0x0a 0x1a 0x0a 0x1b 0x0a 0x89 0x01 0x3c 0x00 0x88 0x13 0x14 0x7c 0x00 0x0a
0x01 0x0a 0x02 0x0a 0x03 0x0a 0x04 0x0a 0x05 0x0a 0x06 0x0a 0x07 0x0a 0x08 0x0a
0x09 0x0a 0x0a 0x0a 0x0b 0x0a 0x0c 0x0a 0x0d 0x0a 0x0e 0x0a 0x0f 0x0a 0x10 0x0a
0x11 0x0a 0x12 0x0a 0x13 0x0a 0x14 0x0a 0x15 0x0a 0x16 0x0a 0x17 0x0a 0x18 0x0a
0x19 0x0a 0x1a 0x0a 0x1b 0x0a 0x89 0x01 0x3c 0x00 0x88 0x13 0x14 0x80 0x00 0x0a
0x01 0x0a 0x02 0x0a 0x03 0x0a 0x04 0x0a 0x05 0x0a 0x06 0x0a 0x07 0x0a 0x08 0x0a
0x09 0x0a 0x0a 0x0a 0x0b 0x0a 0x0c 0x0a 0x0d 0x0a 0x0e 0x0a 0x0f 0x0a 0x10 0x0a
0x11 0x0a 0x12 0x0a 0x13 0x0a 0x14 0x0a 0x15 0x0a 0x16 0x0a 0x17 0x0a 0x18 0x0a
0x19 0x0a 0x1a 0x0a 0x1b 0x0a 0x89 0x01 0x3c 0x00 0x88 0x13 0x14 0x84 0x00 0x0a
0x01 0x0a 0x02 0x0a 0x03 0x0a 0x04 0x0a 0x05 0x0a 0x06 0x0a 0x07 0x0a 0x08 0x0a
0x09 0x0a 0x0a 0x0a 0x0b 0x0a 0x0c 0x0a 0x0d 0x0a 0x0e 0x0a 0x0f 0x0a 0x10 0x0a
0x11 0x0a 0x12 0x0a 0x13 0x0a 0x14 0x0a 0x15 0x0a 0x16 0x0a 0x17 0x0a 0x18 0x0a
0x19 0x0a 0x1a 0x0a 0x1b 0x0a 0x89 0x01 0x3c 0x00 0x88 0x13 0x14 0x88 0x00 0x0a
0x01 0x0a 0x02 0x0a 0x03 0x0a 0x04 0x0a 0x05 0x0a 0x06 0x0a 0x07 0x0a 0x08 0x0a
0x09 0x0a 0x0a 0x0a 0x0b 0x0a 0x0c 0x0a 0x0d 0x0a 0x0e 0x0a 0x0f 0x0a 0x10 0x0a
0x11 0x0a 0x12 0x0a 0x13 0x0a 0x14 0x0a 0x15 0x0a 0x16 0x0a 0x17 0x0a 0x18 0x0a
0x19 0x0a 0x1a 0x0a 0x1b 0x0a 0x89 0x01 0x3c 0x00 0x88 0x13 0x14 0x8c 0x00 0x0a
0x01 0x0a 0x02 0x0a 0x03 0x0a 0x04 0x0a 0x05 0x0a 0x06 0x0a 0x07 0x0a 0x08 0x0a
0x09 0x0a 0x0a 0x0a 0x0b 0x0a 0x0c 0x0a 0x0d 0x0a 0x0e 0x0a 0x0f 0x0a 0x10 0x0a
0x11 0x0a 0x12 0x0a 0x13 0x0a 0x14 0x0a 0x15 0x0a 0x16 0x0a 0x17 0x0a 0x18 0x0a
0x19 0x0a 0x1a 0x0a 0x1b 0x0a 0x89 0x01 0x3c 0x00 0x88 0x13 0x14 0x90 0x00 0x0a
0x01 0x0a 0x02 0x0a 0x03 0x0a 0x04 0x0a 0x05 0x0a 0x06 0x0a 0x07 0x0a 0x08 0x0a
0x09 0x0a 0x0a 0x0a 0x0b 0x0a 0x0c 0x0a 0x0d 0x0a 0x0e 0x0a 0x0f 0x0a 0x10 0x0a
0x11 0x0a 0x12 0x0a 0x13 0x0a 0x14 0x0a 0x15 0x0a 0x16 0x0a 0x17 0x0a 0x18 0x0a
0x19 0x0a 0x1a 0x0a 0x1b 0x0a
	>;

	marvell,caldata_01_txpwrlimit_5g_cfg_set_sub2 = /bits/ 8 <
0x01 0x00 0x06 0x00 0x44 0x01 0x89 0x01 0x3c 0x00 0x88 0x13 0x14 0x95 0x00 0x0a
0x01 0x0a 0x02 0x0a 0x03 0x0a 0x04 0x0a 0x05 0x0a 0x06 0x0a 0x07 0x0a 0x08 0x0a
0x09 0x0a 0x0a 0x0a 0x0b 0x0a 0x0c 0x0a 0x0d 0x0a 0x0e 0x0a 0x0f 0x0a 0x10 0x0a
0x11 0x0a 0x12 0x0a 0x13 0x0a 0x14 0x0a 0x15 0x0a 0x16 0x0a 0x17 0x0a 0x18 0x0a
0x19 0x0a 0x1a 0x0a 0x1b 0x0a 0x89 0x01 0x3c 0x00 0x88 0x13 0x14 0x99 0x00 0x0a
0x01 0x0a 0x02 0x0a 0x03 0x0a 0x04 0x0a 0x05 0x0a 0x06 0x0a 0x07 0x0a 0x08 0x0a
0x09 0x0a 0x0a 0x0a 0x0b 0x0a 0x0c 0x0a 0x0d 0x0a 0x0e 0x0a 0x0f 0x0a 0x10 0x0a
0x11 0x0a 0x12 0x0a 0x13 0x0a 0x14 0x0a 0x15 0x0a 0x16 0x0a 0x17 0x0a 0x18 0x0a
0x19 0x0a 0x1a 0x0a 0x1b 0x0a 0x89 0x01 0x3c 0x00 0x88 0x13 0x14 0x9d 0x00 0x0a
0x01 0x0a 0x02 0x0a 0x03 0x0a 0x04 0x0a 0x05 0x0a 0x06 0x0a 0x07 0x0a 0x08 0x0a
0x09 0x0a 0x0a 0x0a 0x0b 0x0a 0x0c 0x0a 0x0d 0x0a 0x0e 0x0a 0x0f 0x0a 0x10 0x0a
0x11 0x0a 0x12 0x0a 0x13 0x0a 0x14 0x0a 0x15 0x0a 0x16 0x0a 0x17 0x0a 0x18 0x0a
0x19 0x0a 0x1a 0x0a 0x1b 0x0a 0x89 0x01 0x3c 0x00 0x88 0x13 0x14 0xa1 0x00 0x0a
0x01 0x0a 0x02 0x0a 0x03 0x0a 0x04 0x0a 0x05 0x0a 0x06 0x0a 0x07 0x0a 0x08 0x0a
0x09 0x0a 0x0a 0x0a 0x0b 0x0a 0x0c 0x0a 0x0d 0x0a 0x0e 0x0a 0x0f 0x0a 0x10 0x0a
0x11 0x0a 0x12 0x0a 0x13 0x0a 0x14 0x0a 0x15 0x0a 0x16 0x0a 0x17 0x0a 0x18 0x0a
0x19 0x0a 0x1a 0x0a 0x1b 0x0a 0x89 0x01 0x3c 0x00 0x88 0x13 0x14 0xa5 0x00 0x0a
0x01 0x0a 0x02 0x0a 0x03 0x0a 0x04 0x0a 0x05 0x0a 0x06 0x0a 0x07 0x0a 0x08 0x0a
0x09 0x0a 0x0a 0x0a 0x0b 0x0a 0x0c 0x0a 0x0d 0x0a 0x0e 0x0a 0x0f 0x0a 0x10 0x0a
0x11 0x0a 0x12 0x0a 0x13 0x0a 0x14 0x0a 0x15 0x0a 0x16 0x0a 0x17 0x0a 0x18 0x0a
0x19 0x0a 0x1a 0x0a 0x1b 0x0a
	>;

	marvell,caldata_01_txpwrlimit_5g_cfg_set_sub3 = /bits/ 8 <
0x01 0x00 0x06 0x00 0x84 0x03 0x89 0x01 0x3c 0x00 0xa0 0x0f 0x14 0xb7 0x00 0x0a
0x01 0x0a 0x02 0x0a 0x03 0x0a 0x04 0x0a 0x05 0x0a 0x06 0x0a 0x07 0x0a 0x08 0x0a
0x09 0x0a 0x0a 0x0a 0x0b 0x0a 0x0c 0x0a 0x0d 0x0a 0x0e 0x0a 0x0f 0x0a 0x10 0x0a
0x11 0x0a 0x12 0x0a 0x13 0x0a 0x14 0x0a 0x15 0x0a 0x16 0x0a 0x17 0x0a 0x18 0x0a
0x19 0x0a 0x1a 0x0a 0x1b 0x0a 0x89 0x01 0x3c 0x00 0xa0 0x0f 0x14 0xb8 0x00 0x0a
0x01 0x0a 0x02 0x0a 0x03 0x0a 0x04 0x0a 0x05 0x0a 0x06 0x0a 0x07 0x0a 0x08 0x0a
0x09 0x0a 0x0a 0x0a 0x0b 0x0a 0x0c 0x0a 0x0d 0x0a 0x0e 0x0a 0x0f 0x0a 0x10 0x0a
0x11 0x0a 0x12 0x0a 0x13 0x0a 0x14 0x0a 0x15 0x0a 0x16 0x0a 0x17 0x0a 0x18 0x0a
0x19 0x0a 0x1a 0x0a 0x1b 0x0a 0x89 0x01 0x3c 0x00 0xa0 0x0f 0x14 0xb9 0x00 0x0a
0x01 0x0a 0x02 0x0a 0x03 0x0a 0x04 0x0a 0x05 0x0a 0x06 0x0a 0x07 0x0a 0x08 0x0a
0x09 0x0a 0x0a 0x0a 0x0b 0x0a 0x0c 0x0a 0x0d 0x0a 0x0e 0x0a 0x0f 0x0a 0x10 0x0a
0x11 0x0a 0x12 0x0a 0x13 0x0a 0x14 0x0a 0x15 0x0a 0x16 0x0a 0x17 0x0a 0x18 0x0a
0x19 0x0a 0x1a 0x0a 0x1b 0x0a 0x89 0x01 0x3c 0x00 0xa0 0x0f 0x14 0xbb 0x00 0x0a
0x01 0x0a 0x02 0x0a 0x03 0x0a 0x04 0x0a 0x05 0x0a 0x06 0x0a 0x07 0x0a 0x08 0x0a
0x09 0x0a 0x0a 0x0a 0x0b 0x0a 0x0c 0x0a 0x0d 0x0a 0x0e 0x0a 0x0f 0x0a 0x10 0x0a
0x11 0x0a 0x12 0x0a 0x13 0x0a 0x14 0x0a 0x15 0x0a 0x16 0x0a 0x17 0x0a 0x18 0x0a
0x19 0x0a 0x1a 0x0a 0x1b 0x0a 0x89 0x01 0x3c 0x00 0xa0 0x0f 0x14 0xbc 0x00 0x0a
0x01 0x0a 0x02 0x0a 0x03 0x0a 0x04 0x0a 0x05 0x0a 0x06 0x0a 0x07 0x0a 0x08 0x0a
0x09 0x0a 0x0a 0x0a 0x0b 0x0a 0x0c 0x0a 0x0d 0x0a 0x0e 0x0a 0x0f 0x0a 0x10 0x0a
0x11 0x0a 0x12 0x0a 0x13 0x0a 0x14 0x0a 0x15 0x0a 0x16 0x0a 0x17 0x0a 0x18 0x0a
0x19 0x0a 0x1a 0x0a 0x1b 0x0a 0x89 0x01 0x3c 0x00 0xa0 0x0f 0x14 0xbd 0x00 0x0a
0x01 0x0a 0x02 0x0a 0x03 0x0a 0x04 0x0a 0x05 0x0a 0x06 0x0a 0x07 0x0a 0x08 0x0a
0x09 0x0a 0x0a 0x0a 0x0b 0x0a 0x0c 0x0a 0x0d 0x0a 0x0e 0x0a 0x0f 0x0a 0x10 0x0a
0x11 0x0a 0x12 0x0a 0x13 0x0a 0x14 0x0a 0x15 0x0a 0x16 0x0a 0x17 0x0a 0x18 0x0a
0x19 0x0a 0x1a 0x0a 0x1b 0x0a 0x89 0x01 0x3c 0x00 0xa0 0x0f 0x14 0xc0 0x00 0x0a
0x01 0x0a 0x02 0x0a 0x03 0x0a 0x04 0x0a 0x05 0x0a 0x06 0x0a 0x07 0x0a 0x08 0x0a
0x09 0x0a 0x0a 0x0a 0x0b 0x0a 0x0c 0x0a 0x0d 0x0a 0x0e 0x0a 0x0f 0x0a 0x10 0x0a
0x11 0x0a 0x12 0x0a 0x13 0x0a 0x14 0x0a 0x15 0x0a 0x16 0x0a 0x17 0x0a 0x18 0x0a
0x19 0x0a 0x1a 0x0a 0x1b 0x0a 0x89 0x01 0x3c 0x00 0xa0 0x0f 0x14 0xc4 0x00 0x0a
0x01 0x0a 0x02 0x0a 0x03 0x0a 0x04 0x0a 0x05 0x0a 0x06 0x0a 0x07 0x0a 0x08 0x0a
0x09 0x0a 0x0a 0x0a 0x0b 0x0a 0x0c 0x0a 0x0d 0x0a 0x0e 0x0a 0x0f 0x0a 0x10 0x0a
0x11 0x0a 0x12 0x0a 0x13 0x0a 0x14 0x0a 0x15 0x0a 0x16 0x0a 0x17 0x0a 0x18 0x0a
0x19 0x0a 0x1a 0x0a 0x1b 0x0a 0x89 0x01 0x3c 0x00 0x88 0x13 0x14 0x07 0x00 0x0a
0x01 0x0a 0x02 0x0a 0x03 0x0a 0x04 0x0a 0x05 0x0a 0x06 0x0a 0x07 0x0a 0x08 0x0a
0x09 0x0a 0x0a 0x0a 0x0b 0x0a 0x0c 0x0a 0x0d 0x0a 0x0e 0x0a 0x0f 0x0a 0x10 0x0a
0x11 0x0a 0x12 0x0a 0x13 0x0a 0x14 0x0a 0x15 0x0a 0x16 0x0a 0x17 0x0a 0x18 0x0a
0x19 0x0a 0x1a 0x0a 0x1b 0x0a 0x89 0x01 0x3c 0x00 0x88 0x13 0x14 0x08 0x00 0x0a
0x01 0x0a 0x02 0x0a 0x03 0x0a 0x04 0x0a 0x05 0x0a 0x06 0x0a 0x07 0x0a 0x08 0x0a
0x09 0x0a 0x0a 0x0a 0x0b 0x0a 0x0c 0x0a 0x0d 0x0a 0x0e 0x0a 0x0f 0x0a 0x10 0x0a
0x11 0x0a 0x12 0x0a 0x13 0x0a 0x14 0x0a 0x15 0x0a 0x16 0x0a 0x17 0x0a 0x18 0x0a
0x19 0x0a 0x1a 0x0a 0x1b 0x0a 0x89 0x01 0x3c 0x00 0x88 0x13 0x14 0x0b 0x00 0x0a
0x01 0x0a 0x02 0x0a 0x03 0x0a 0x04 0x0a 0x05 0x0a 0x06 0x0a 0x07 0x0a 0x08 0x0a
0x09 0x0a 0x0a 0x0a 0x0b 0x0a 0x0c 0x0a 0x0d 0x0a 0x0e 0x0a 0x0f 0x0a 0x10 0x0a
0x11 0x0a 0x12 0x0a 0x13 0x0a 0x14 0x0a 0x15 0x0a 0x16 0x0a 0x17 0x0a 0x18 0x0a
0x19 0x0a 0x1a 0x0a 0x1b 0x0a 0x89 0x01 0x3c 0x00 0x88 0x13 0x14 0x0c 0x00 0x0a
0x01 0x0a 0x02 0x0a 0x03 0x0a 0x04 0x0a 0x05 0x0a 0x06 0x0a 0x07 0x0a 0x08 0x0a
0x09 0x0a 0x0a 0x0a 0x0b 0x0a 0x0c 0x0a 0x0d 0x0a 0x0e 0x0a 0x0f 0x0a 0x10 0x0a
0x11 0x0a 0x12 0x0a 0x13 0x0a 0x14 0x0a 0x15 0x0a 0x16 0x0a 0x17 0x0a 0x18 0x0a
0x19 0x0a 0x1a 0x0a 0x1b 0x0a 0x89 0x01 0x3c 0x00 0x88 0x13 0x14 0x10 0x00 0x0a
0x01 0x0a 0x02 0x0a 0x03 0x0a 0x04 0x0a 0x05 0x0a 0x06 0x0a 0x07 0x0a 0x08 0x0a
0x09 0x0a 0x0a 0x0a 0x0b 0x0a 0x0c 0x0a 0x0d 0x0a 0x0e 0x0a 0x0f 0x0a 0x10 0x0a
0x11 0x0a 0x12 0x0a 0x13 0x0a 0x14 0x0a 0x15 0x0a 0x16 0x0a 0x17 0x0a 0x18 0x0a
0x19 0x0a 0x1a 0x0a 0x1b 0x0a 0x89 0x01 0x3c 0x00 0x88 0x13 0x14 0x22 0x00 0x0a
0x01 0x0a 0x02 0x0a 0x03 0x0a 0x04 0x0a 0x05 0x0a 0x06 0x0a 0x07 0x0a 0x08 0x0a
0x09 0x0a 0x0a 0x0a 0x0b 0x0a 0x0c 0x0a 0x0d 0x0a 0x0e 0x0a 0x0f 0x0a 0x10 0x0a
0x11 0x0a 0x12 0x0a 0x13 0x0a 0x14 0x0a 0x15 0x0a 0x16 0x0a 0x17 0x0a 0x18 0x0a
0x19 0x0a 0x1a 0x0a 0x1b 0x0a
	>;
};

&pinctrl {
	tpm {
		h1_int_od_l: h1-int-od-l {
			rockchip,pins = <0 RK_PA5 RK_FUNC_GPIO &pcfg_pull_up>;
		};
	};
};
